AUTOSAR XML (schema 4-3-0)
package /Vehicle/Clusters
  can cluster VehicleCan
package /Vehicle/Interfaces
  sender receiver interface IF_VehicleSpeed
package /Vehicle/Signals
  i signal VehicleSpeed
package /Vehicle/Pdus
  pdu Pdu_VehicleSpeed: length=5
    i-signal-to-i-pdu-mappings:
      isignal to i pdu mapping VehicleSpeedMapping: i-signal=VehicleSpeed
package /Vehicle/FrameMappings
  pdu to frame mapping Map_VehicleSpeed: frame=Frame_VehicleSpeed, i-pdu=Pdu_VehicleSpeed
package /Vehicle/Frames
  can frame Frame_VehicleSpeed: frame-length=64
package /Vehicle/SwCs
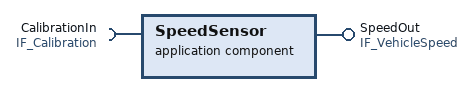
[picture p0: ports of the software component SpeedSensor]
  application sw component type SpeedSensor
    provide port SpeedOut: provided-interface=IF_VehicleSpeed
    require port CalibrationIn: required-interface=IF_Calibration
